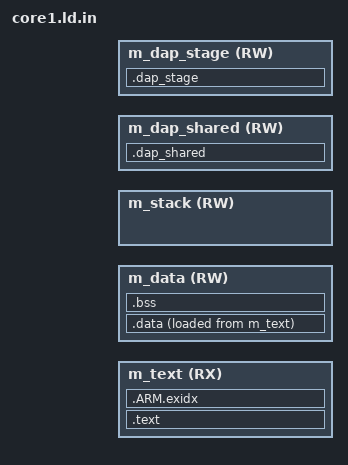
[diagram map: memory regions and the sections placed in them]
/* CPU 1's image. CMakeLists.txt fills in the layout it shares with CPU 0's link script, and
 * core1_image.S embeds the result at @CORE1_FLASH_ORIGIN@ in CPU 0's image. */
ENTRY(core1_reset)

MEMORY
{
  m_text       (RX) : ORIGIN = @CORE1_FLASH_ORIGIN@, LENGTH = @CORE1_FLASH_LENGTH@
  m_data       (RW) : ORIGIN = @CORE1_RAM_ORIGIN@, LENGTH = @CORE1_RAM_LENGTH@
  m_stack      (RW) : ORIGIN = @CORE1_STACK_ORIGIN@, LENGTH = @CORE1_STACK_LENGTH@
  m_dap_shared (RW) : ORIGIN = @DAP_SHARED_ORIGIN@, LENGTH = @DAP_SHARED_LENGTH@
  m_dap_stage  (RW) : ORIGIN = @DAP_STAGE_ORIGIN@, LENGTH = @DAP_STAGE_LENGTH@
}

SECTIONS
{
  .text :
  {
    KEEP(*(.core1_vectors))
    *(EXCLUDE_FILE(*mem.S.obj) .text EXCLUDE_FILE(*mem.S.obj) .text*)
    *(.rodata .rodata*)
    . = ALIGN(4);
  } > m_text

  .ARM.exidx :
  {
    *(.ARM.exidx* .gnu.linkonce.armexidx.*)
  } > m_text

  /* The bit paths that run from RAM are .ramfunc, and core1_start.S copies them with the rest.
   * memcpy, which copies every request and reply, goes last so that it moves nothing else.
   * core1_start.S copies .data with a loop of its own, so nothing calls memcpy before it is there. */
  .data : ALIGN(4)
  {
    __data_start__ = .;
    *(.ramfunc*)
    *(.data .data*)
    *mem.S.obj(.text .text*)
    . = ALIGN(4);
    __data_end__ = .;
  } > m_data AT > m_text
  __data_load__ = LOADADDR(.data);

  .bss (NOLOAD) : ALIGN(4)
  {
    __bss_start__ = .;
    *(.bss .bss* COMMON)
    . = ALIGN(4);
    __bss_end__ = .;
  } > m_data

  .dap_shared (NOLOAD) :
  {
    KEEP(*(.dap_shared))
  } > m_dap_shared

  .dap_stage (NOLOAD) :
  {
    KEEP(*(.dap_stage))
  } > m_dap_stage

  /* newlib's snprintf links its allocator, whose sbrk starts at `end`. Nothing here allocates. */
  PROVIDE(end = __bss_end__);

  __core1_stack_top = ORIGIN(m_stack) + LENGTH(m_stack);
}
